# CC2538SF53 register map
File version: 1
CPU: CM3 r2p1, little endian, no MPU, no FPU, 3 interrupt priority bits
Registers are 32-bit, read-write, reset 0x0 unless marked. A register's access mark holds for its fields unless they carry their own. Offsets are from the block's base; [hi:lo] are bit positions; {n}, {i} and the like mark numbered series.

## RFCORE_FFSM
Base 0x40088500
0x80 SRCRESMASK0 — Source address matching result This register is stored in RAM; the reset value is undefined.
  [7:0] SRCRESMASK0 — Extended address matching When there is a match on entry ext_n, bits 2n and 2n + 1 are set in SRCRESMASK.
0x84 SRCRESMASK1 — Source address matching result This register is stored in RAM; the reset value is undefined.
  [7:0] SRCRESMASK1 — Short address matching When there is a match on entry panid_n + short_n, bit n is set in SRCRESMASK.
0x88 SRCRESMASK2 — Source address matching result This register is stored in RAM; the reset value is undefined.
  [7:0] SRCRESMASK2 — 24-bit mask that indicates source address match for each individual entry in the source address table
0x8C SRCRESINDEX — Source address matching result This register is stored in RAM; the reset value is undefined.
  [7:0] SRCRESINDEX — The bit index of the least-significant entry (0-23 for short addresses or 0-11 for extended addresses) in SRCRESMASK, or 0x3F when there is no source match On a match, bit 5 is 0 when the match is on a short address and 1 when it is on an extended address. On a match, bit 6 is 1 when the conditions for automatic pending bit in acknowledgment have been met (see the description of SRCMATCH.AUTOPEND). The bit does not indicate if the acknowledgment is actually transmitted, and does not consider the PENDING_OR register bit and the SACK/SACKPEND/SNACK strobes.
0x90 SRCEXTPENDEN0 — Source address matching control This register is stored in RAM; the reset value is undefined.
  [7:0] SRCEXTPENDEN0 — 8 LSBs of the 24-bit mask that enables or disables automatic pending for each of the 12 extended addresses. Entry n is mapped to SRCEXTPENDEN[2n]. All SRCEXTPENDEN[2n + 1] bits are don't care.
0x94 SRCEXTPENDEN1 — Source address matching control This register is stored in RAM; the reset value is undefined.
  [7:0] SRCEXTPENDEN1 — 8 middle bits of the 24-bit mask that enables or disables automatic pending for each of the 12 extended addresses Entry n is mapped to SRCEXTPENDEN[2n]. All SRCEXTPENDEN[2n + 1] bits are don't care.
0x98 SRCEXTPENDEN2 — Source address matching control This register is stored in RAM; the reset value is undefined.
  [7:0] SRCEXTPENDEN2 — 8 MSBs of the 24-bit mask that enables or disables automatic pending for each of the 12 extended addresses Entry n is mapped to SRCEXTPENDEN[2n]. All SRCEXTPENDEN[2n + 1] bits are don't care.
0x9C SRCSHORTPENDEN0 — Source address matching control This register is stored in RAM; the reset value is undefined.
  [7:0] SRCSHORTPENDEN0 — 8 LSBs of the 24-bit mask that enables or disables automatic pending for each of the 24 short addresses
0xA0 SRCSHORTPENDEN1 — Source address matching control This register is stored in RAM; the reset value is undefined.
  [7:0] SRCSHORTPENDEN1 — 8 middle bits of the 24-bit mask that enables or disables automatic pending for each of the 24 short addresses
0xA4 SRCSHORTPENDEN2 — Source address matching control This register is stored in RAM; the reset value is undefined.
  [7:0] SRCSHORTPENDEN2 — 8 MSBs of the 24-bit mask that enables or disables automatic pending for each of the 24 short addresses
{0xA8+4i} EXT_ADDR{i} (i=0..7) — Local address information This register is stored in RAM; the reset value is undefined.
  [7:0] EXT_ADDR{i} — EXT_ADDR[{8i+7}:{8i}] The IEEE extended address used during destination address filtering
0xC8 PAN_ID0 — Local address information This register is stored in RAM; the reset value is undefined.
  [7:0] PAN_ID0 — PAN_ID[7:0] The PAN ID used during destination address filtering
0xCC PAN_ID1 — Local address information This register is stored in RAM; the reset value is undefined.
  [7:0] PAN_ID1 — PAN_ID[15:8] The PAN ID used during destination address filtering
0xD0 SHORT_ADDR0 — Local address information This register is stored in RAM; the reset value is undefined.
  [7:0] SHORT_ADDR0 — SHORT_ADDR[7:0] The short address used during destination address filtering
0xD4 SHORT_ADDR1 — Local address information This register is stored in RAM; the reset value is undefined.
  [7:0] SHORT_ADDR1 — SHORT_ADDR[15:8] The short address used during destination address filtering

## ANA_REGS
Base 0x400D6000
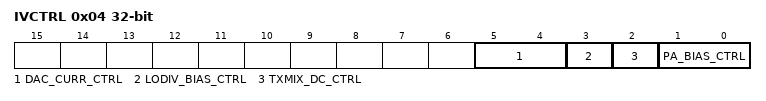
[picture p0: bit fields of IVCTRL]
0x04 IVCTRL — Analog control register
  [5:4] DAC_CURR_CTRL — Controls bias current to DAC 00: 100% IVREF, 0% IREF bias 01: 60% IVREF, 40% IREF bias 10: 40% IVREF, 60% IREF bias 11: 0% IVREF, 100% IREF bias
  [3] LODIV_BIAS_CTRL — Controls bias current to LODIV 1: PTAT bias 0: IVREF bias
  [2] TXMIX_DC_CTRL — Controls DC bias in TXMIX
  [1:0] PA_BIAS_CTRL — Controls bias current to PA 00: IREF bias 01: IREF and IVREF bias (CC2530 mode) 10: PTAT bias 11: Increased PTAT slope bias

## STTEST
Base 0x40110000
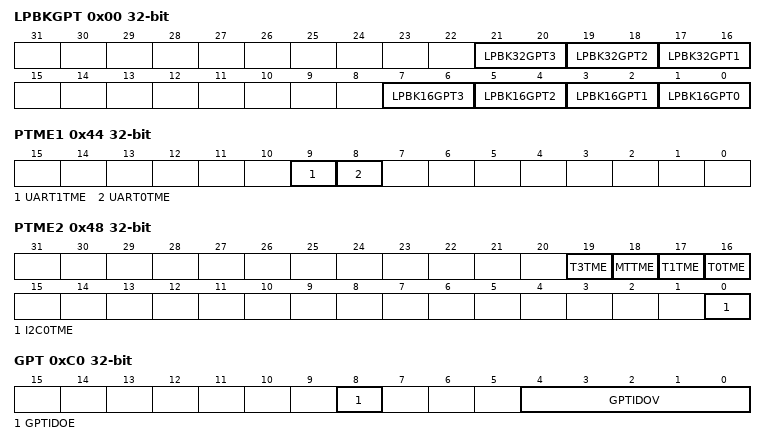
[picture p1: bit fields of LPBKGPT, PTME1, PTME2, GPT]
0x00 LPBKGPT — GPTIMER Internal loopback
  [21:20] LPBK32GPT3 — GPTimer3 32-bit RTC loopback modes 00: Normal operation 01: GPT0 GPTimerA PWM connected to GPT3 capture 10: GPT0 capture connected to GPT3 PWM GPTimer A 11: Reserved, defaults to normal operation
  [19:18] LPBK32GPT2 — GPTimer2 32-bit RTC loopback modes 00: Normal operation 01: GPT0 Timer A PWM connected to GPT2 capture 10: GPT0 capture connected to GPT2 PWM Timer A 11: Reserved, defaults to normal operation
  [17:16] LPBK32GPT1 — GPTimer1 32-bit RTC loopback modes 00: Normal operation 01: GPT0 timerA PWM connected to GPT1 capture 10: GPT0 capture connected to GPT1 PWM Timer A 11: Reserved, defaults to normal operation
  [2n+1:2n] LPBK16GPT{n} (n=0..3) — GPTimer{n} 16-bit loopback modes 00: Normal operation 01: Timer A PWM connected to Timer B capture 10: Timer A capture connected to Timer B PWM 11: Reserved, defaults to normal operation
0x04 LPBKUART — UART internal loopback
  [0] LPBKUART — UART0/1 loopback mode 0: Normal operation 1: UART0 TX (RX) connected to UART1 RX (TX)
0x0C LPBKI2C — I2C internal loopback
  [0] LPBKI2C — I2C0 Master/slave loopback mode 0: Normal mode
0x44 PTME1 — Peripheral test mode enable 1
  [9] UART1TME — UART1 test mode enable
  [8] UART0TME — UART0 test mode enable
0x48 PTME2 — Peripheral test mode enable 2
  [19] T3TME — Timer3 test mode enable
  [18] MTTME — MacTimer test mode enable
  [17] T1TME — Timer1 test mode enable
  [16] T0TME — Timer0 test mode enable
  [0] I2C0TME — I2C 0 test mode enable
0xC0 GPT — GPTIMER override values
  [8] GPTIDOE — GPTimer increment/decrement override enable
  [4:0] GPTIDOV — GPTimer increment/decrement override value

## CCTEST
Base 0x44010000
0x00 IO — Output strength control
  [0] SC — I/O strength control bit Common to all digital output pads Should be set when unregulated voltage is below approximately 2.6 V.
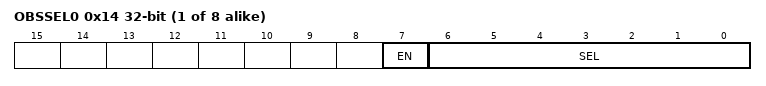
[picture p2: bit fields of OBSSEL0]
{0x14+4i} OBSSEL{i} (i=0..7) — Select output signal on observation output {i}
  [7] EN — Observation output {i} enable control for PC{i} 0: Observation output disabled 1: Observation output enabled Note: If enabled, this overwrites the standard GPIO behavior of PC{i}.
  [6:0] SEL — n - obs_sigs[n] output on output {i}: 0: rfc_obs_sig0 1: rfc_obs_sig1 2: rfc_obs_sig2 Others: Reserved
0x34 TR0 — Test register 0
  [1] ADCTM — Set to 1 to connect the temperature sensor to the SOC_ADC. See also RFCORE_XREG_ATEST register description to enable the temperature sensor.
0x50 USBCTRL — USB PHY stand-by control
  [0] USB_STB — USB PHY stand-by override bit When this bit is cleared to 0 (default state) the USB module cannot change the stand-by mode of the PHY (USB pads) and the PHY is forced out of stand-by mode. This bit must be 1 as well as the stand-by control from the USB controller, before the mode of the PHY is stand-by.
